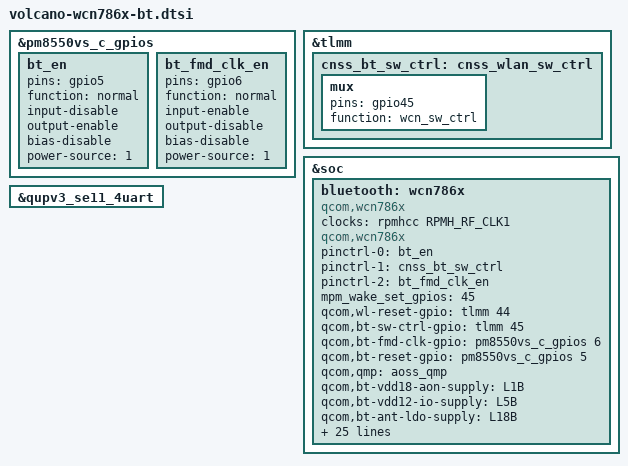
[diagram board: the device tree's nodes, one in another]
// SPDX-License-Identifier: BSD-3-Clause

/*
 * Copyright (c) 2024 Qualcomm Innovation Center, Inc. All rights reserved.
 */

#include <dt-bindings/interconnect/qcom,volcano.h>
#include <dt-bindings/clock/qcom,rpmh.h>

&pm8550vs_c_gpios {
	bt_en: bt_en {
		pins = "gpio5";
		function = "normal";
		input-disable;
		output-enable;
		bias-disable;
		power-source = <1>;
	};
	bt_fmd_clk_en: bt_fmd_clk_en {
		pins = "gpio6";
		function = "normal";
		input-enable;
		output-disable;
		bias-disable;
		power-source = <1>;
	};
};

&tlmm {
	cnss_bt_sw_ctrl: cnss_wlan_sw_ctrl {
		mux {
			pins = "gpio45";
			function = "wcn_sw_ctrl";
		};
	};
};

&soc {
	bluetooth: wcn786x {
			compatible = "qcom,wcn786x";
			//nvmem-cells = <&fmd_set>;
			//nvmem-cell-names = "fmd_set";
			clocks = <&rpmhcc RPMH_RF_CLK1>;
			clock-names = "bt_rf_clk1";
			qcom,wcn786x;
			pinctrl-names = "bt_en", "sw_ctrl", "bt_fmd_clk_en";
			pinctrl-0 = <&bt_en>;
			pinctrl-1 = <&cnss_bt_sw_ctrl>;
			pinctrl-2 = <&bt_fmd_clk_en>;
			/* List of GPIOs to be setup for interrupt wakeup capable*/
			mpm_wake_set_gpios = <45>;
			qcom,wl-reset-gpio = <&tlmm 44 0>; /* WL_EN */
			qcom,bt-sw-ctrl-gpio = <&tlmm 45 0>; /* SW_CTRL */
			qcom,bt-fmd-clk-gpio = <&pm8550vs_c_gpios 6 0>; /* FMD_CLK_CTRL */
			qcom,bt-reset-gpio = <&pm8550vs_c_gpios 5 0>; /* BT_EN */
			qcom,qmp = <&aoss_qmp>;

			qcom,bt-vdd18-aon-supply  = <&L1B>;   /* VDD1P8_AON */
			qcom,bt-vdd12-io-supply   = <&L5B>;   /* VDD1P2_IO */
			qcom,bt-ant-ldo-supply    = <&L18B>;   /* AV91C_VDD Extractor */
			qcom,bt-vdd-dig-supply    = <&S1L>;   /* BT CX_MX LDO */
			qcom,bt-vdd-aon-supply    = <&S1K>;   /* RFA_CMN/AON */
			//qcom,bt-vdd-rfa0p75-supply = <&S1K>;  /* RFA_OP75 */
			qcom,bt-vdd-rfa1p8-supply  = <&S1B>;  /* RFA_1P8 */
			qcom,bt-vdd-rfa1p25-supply = <&S2B>; /* RFA_1P2 */

			qcom,bt-vdd18-aon-config  = <1800000 1800000 0 1 1>;
			qcom,bt-vdd12-io-config   = <1200000 1200000 0 1 1>;
			qcom,bt-ant-ldo-config    = <2800000 2800000 0 1 0>;
			qcom,bt-vdd-dig-config    = <876000 1000000 0 1 0>;
			qcom,bt-vdd-aon-config    = <665000 1004000 0 0 0>;
			//qcom,bt-vdd-rfa0p75-config = <876000 1004000 0 0 0>;
			qcom,bt-vdd-rfa1p8-config = <1860000 2000000 0 1 0>;
			qcom,bt-vdd-rfa1p25-config  = <1312000 1340000 0 1 0>;

			/* WLAN regulator for FMD feature */
			qcom,bt-vdd-wlan-aon-supply = <&S1K>;
			qcom,bt-vdd-wlan-aon-config = <665000 1036000 0 0 1>;

			qcom,pdc_init_table =
				"{class: wlan_pdc, ss: rf, res: s2b.v, dwnval: 1244}",
				"{class: wlan_pdc, ss: rf, res: s3b.v, enable: 0}",
				"{class: wlan_pdc, ss: rf, res: l5b.m, enable: 1}",
				"{class: wlan_pdc, ss: rf, res: g1f.e, enable: 0}",
				"{class: wlan_pdc, ss: rf, res: l1b.m, enable: 1}",
				"{class: wlan_pdc, ss: rf, res: s3b.m, enable: 0}",
				"{class: wlan_pdc, ss: bb, res: pdc, enable: 1}";
	};
};

//&swr4 {
//	btswr_slave: btswr-slave {
//		compatible = "qcom,btfmswr_slave";
//		reg = <0x02 0x08170220>;
//	};
//};

//uart instance
&qupv3_se11_4uart {
	status = "ok";
};

//spi instance
//&qupv3_se2_spi {
//	status = "ok";
//};
